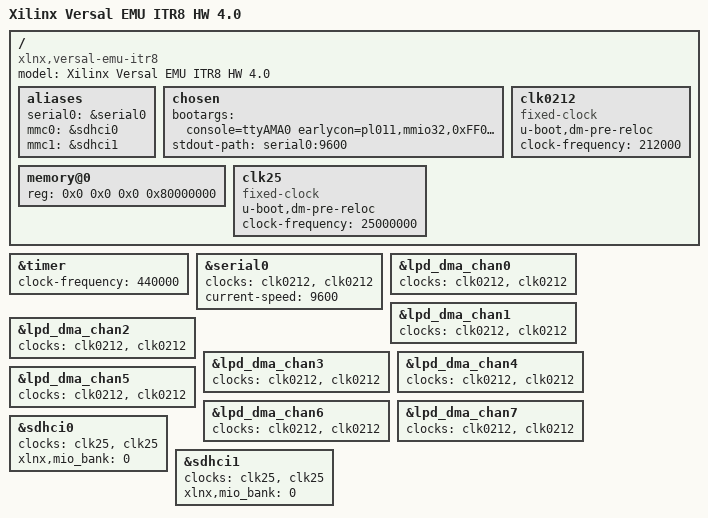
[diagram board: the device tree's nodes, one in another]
/ {
	compatible = "xlnx,versal-emu-itr8", "xlnx,versal-emu", "xlnx,versal";
	#address-cells = <2>;
	#size-cells = <2>;
	model = "Xilinx Versal EMU ITR8 HW 4.0";

	aliases {
		serial0 = &serial0;
		mmc0 = &sdhci0;
		mmc1 = &sdhci1;
	};

	chosen {
		bootargs = "console=ttyAMA0 earlycon=pl011,mmio32,0xFF000000,9600n8 clk_ignore_unused maxcpus=1";
		stdout-path = "serial0:9600";
	};

	memory@0 {
		device_type = "memory";
		reg = <0x0 0x0 0x0 0x80000000>;
	};

	clk0212: clk0212 {
		u-boot,dm-pre-reloc;
		compatible = "fixed-clock";
		#clock-cells = <0x0>;
		clock-frequency = <212000>;
	};

	clk25: clk25 {
		u-boot,dm-pre-reloc;
		compatible = "fixed-clock";
		#clock-cells = <0x0>;
		clock-frequency = <25000000>;
	};
};

&timer {
        clock-frequency = <440000>;
};

&serial0 {
        status = "okay";
        clocks = <&clk0212 &clk0212>;
	current-speed = <9600>;
};

&lpd_dma_chan0 {
	status = "okay";
	clocks = <&clk0212 &clk0212>;
};

&lpd_dma_chan0 {
	status = "okay";
	clocks = <&clk0212 &clk0212>;
};

&lpd_dma_chan1 {
	status = "okay";
	clocks = <&clk0212 &clk0212>;
};

&lpd_dma_chan2 {
	status = "okay";
	clocks = <&clk0212 &clk0212>;
};

&lpd_dma_chan3 {
	status = "okay";
	clocks = <&clk0212 &clk0212>;
};

&lpd_dma_chan4 {
	status = "okay";
	clocks = <&clk0212 &clk0212>;
};

&lpd_dma_chan5 {
	status = "okay";
	clocks = <&clk0212 &clk0212>;
};

&lpd_dma_chan6 {
	status = "okay";
	clocks = <&clk0212 &clk0212>;
};

&lpd_dma_chan7 {
	status = "okay";
	clocks = <&clk0212 &clk0212>;
};

&sdhci0 {
	status = "okay";
	clocks = <&clk25 &clk25>;
	xlnx,mio_bank = <0>;
};

&sdhci1 {
	status = "okay";
	clocks = <&clk25 &clk25>;
	xlnx,mio_bank = <0>;
};
